# C64 register map
Vendor: Commodore Business Machines; Series: Commodore 64; File version: 0.1.0
CPU: other r0p0, little endian, no MPU, no FPU, 2 interrupt priority bits
Registers are 8-bit, read-write, no defined reset value unless marked. A register's access mark holds for its fields unless they carry their own. Offsets are from the block's base; [hi:lo] are bit positions; lines under a group give offsets from that group; {n}, {i} and the like mark numbered series.

## CPUPORT — MOS 6510 on-chip I/O port at addresses 0x0000-0x0001: memory banking control and Datassette lines. KERNAL reset writes D6510=0x2F, R6510=0x37. baseAddress 0 puts D6510 at address 0, where the generated Periph Deref would form a null reference, so this peripheral is hand-written over the generated output by svd/generate_c64_pac.sh, Fix 5.
Base 0x00000000
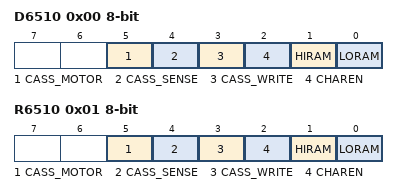
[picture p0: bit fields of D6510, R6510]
0x00 D6510 — Data-direction register for the 6510's on-chip I/O port (R6510): one bit per line, 1 = output, 0 = input. The 6510 is a 6502 with this 6-bit port bolted on; it is the whole reason the C64 can map 64 KiB RAM + 20 KiB ROM + 4 KiB I/O (= 88 KiB (!)) into a single 64 KiB address space with no external MMU. KERNAL reset writes 0x2F (0b0010_1111): lines 0-3 and 5 are outputs, line 4 (cassette sense) is an input, and bits 6-7 are unused (no port line). Written before R6510 during reset. The RAM byte physically at 0x0000 still exists but is hidden behind the port.
  [all] fields
    0=Input; 1=Output
  [5] CASS_MOTOR — Direction of the CASS_MOTOR line (R6510 bit 5)
  [4] CASS_SENSE — Direction of the CASS_SENSE line (R6510 bit 4)
  [3] CASS_WRITE — Direction of the CASS_WRITE line (R6510 bit 3)
  [2] CHAREN — Direction of the CHAREN line (R6510 bit 2)
  [1] HIRAM — Direction of the HIRAM line (R6510 bit 1)
  [0] LORAM — Direction of the LORAM line (R6510 bit 0)
0x01 R6510 — Banking and Datassette port. Reads return pin state for input bits.
  [5] CASS_MOTOR — Datassette motor: 0 = on, 1 = off
    0=Running; 1=Stopped
  [4] CASS_SENSE — Datassette sense (input): 0 = a button is pressed
    0=Pressed; 1=Released
  [3] CASS_WRITE — Datassette write line
  [2] CHAREN — 1 = I/O at 0xD000-0xDFFF, 0 = character ROM (RAM if LORAM=HIRAM=0)
    0=CharRom; 1=Io
  [1] HIRAM — 1 = KERNAL ROM at 0xE000-0xFFFF, 0 = RAM
    0=Ram; 1=KernalRom
  [0] LORAM — 1 = BASIC ROM at 0xA000-0xBFFF (with HIRAM=1), 0 = RAM
    0=Ram; 1=BasicRom

## SID — SID sound interface (6581/8580) at 0xD400. Register image repeats every 0x20 bytes through 0xD7FF. Voice and filter registers are write-only: reads return a decaying copy of the last value written to any SID register, not register contents (not modeled here). POTX/POTY digitize the RC discharge time of the paddle inputs selected by CIA1.CIAPRA bits 6-7.
Base 0x0000D400
{0x0+7i} VOICE{i} (i=0..2) group — Voice {i}
  0x00 FRELO wo — Oscillator frequency bits 7:0
    [7:0] FREQUENCY — Oscillator frequency, low 8 bits
  0x01 FREHI wo — Oscillator frequency bits 15:8
    [7:0] FREQUENCY — Oscillator frequency, high 8 bits
  0x02 PWLO wo — Pulse width bits 7:0
    [7:0] PULSE_WAVEFORM_WIDTH — Pulse waveform width, low 8 bits
  0x03 PWHI wo — Pulse width bits 11:8 (bits 4-7 unused)
    [3:0] PULSE_WAVEFORM_WIDTH — Pulse width bits 11:8
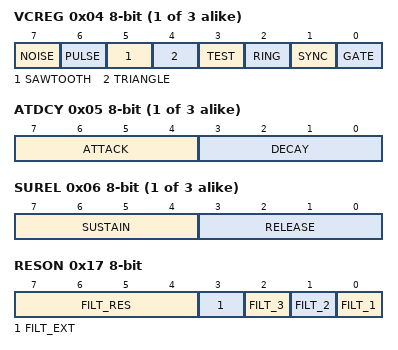
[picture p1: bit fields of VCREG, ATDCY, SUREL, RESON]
  0x04 VCREG wo — Voice control
    [7] NOISE — Noise waveform
      0=Disabled; 1=Enabled
    [6] PULSE — Pulse waveform
      0=Disabled; 1=Enabled
    [5] SAWTOOTH — Sawtooth waveform
      0=Disabled; 1=Enabled
    [4] TRIANGLE — Triangle waveform
      0=Disabled; 1=Enabled
    [3] TEST — Reset and hold the oscillator (Disabled = held)
      0=Enabled; 1=Disabled
    [2] RING — Ring modulation with the preceding voice (triangle output)
      0=Disabled; 1=Enabled
    [1] SYNC — Hard-sync oscillator with the preceding voice
      0=Disabled; 1=Enabled
    [0] GATE — Envelope gate: 0 starts release, 1 starts attack-decay-sustain
      0=StartR; 1=StartADS
  0x05 ATDCY wo — Envelope attack/decay
    [7:4] ATTACK — Attack rate
    [3:0] DECAY — Decay rate
  0x06 SUREL wo — Envelope sustain/release
    [7:4] SUSTAIN — Sustain level
    [3:0] RELEASE — Release rate
0x15 CUTLO wo — Filter cutoff bits 2:0 (bits 3-7 unused)
  [2:0] FILTER_CUTOFF_FREQ — Filter cutoff bits 2:0
0x16 CUTHI wo — Filter cutoff bits 10:3
  [7:0] FILTER_CUTOFF_FREQ — Filter cutoff frequency, high 8 bits
0x17 RESON wo — Filter resonance and routing
  [7:4] FILT_RES — Filter resonance (0-15)
  [3] FILT_EXT — Route external input through the filter
    0=Disabled; 1=Enabled
  [2] FILT_3 — Route voice 3 through the filter
    0=Disabled; 1=Enabled
  [1] FILT_2 — Route voice 2 through the filter
    0=Disabled; 1=Enabled
  [0] FILT_1 — Route voice 1 through the filter
    0=Disabled; 1=Enabled
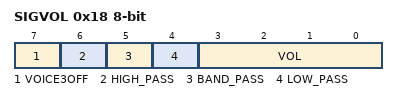
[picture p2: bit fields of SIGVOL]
0x18 SIGVOL wo — Filter mode and master volume
  [7] VOICE3OFF — Voice 3 audio output (Disabled = disconnected)
    0=Enabled; 1=Disabled
  [6] HIGH_PASS — High-pass filter output
    0=Disabled; 1=Enabled
  [5] BAND_PASS — Band-pass filter output
    0=Disabled; 1=Enabled
  [4] LOW_PASS — Low-pass filter output
    0=Disabled; 1=Enabled
  [3:0] VOL — Master volume (0-15)
0x19 POTX ro — Paddle X digitized position (updated every 512 cycles)
0x1A POTY ro — Paddle Y digitized position
0x1B RANDOM ro — Voice 3 oscillator output (usable as entropy with noise waveform)
0x1C ENV3 ro — Voice 3 envelope output

## COLORRAM — 1024 nybbles of static color RAM at 0xD800-0xDBFF, always visible when I/O is banked in, independent of the VIC bank. Only bits 3:0 are stored; bits 7:4 read as whatever the VIC last placed on its data bus (treat reads as 4-bit). The first 1000 (0xD800-0xDBE7) back the 40x25 text/bitmap display; the remaining 24 (0xDBE8-0xDBFF) are unused by the VIC but are real 4-bit cells, usable as scratch.
Base 0x0000D800
{0x0+i} CRAM{i} (i=0..1023) — Color cell (bits 3:0)
  [3:0] COLOR — Color of this cell
    0=Black; 1=White; 2=Red; 3=Cyan; 4=Purple; 5=Green; 6=Blue; 7=Yellow; 8=Orange; 9=Brown; 10=LightRed; 11=DarkGray; 12=MediumGray; 13=LightGreen; 14=LightBlue; 15=LightGray

## IO1 — Expansion (cartridge) port chip-select window: the PLA asserts /IO1 for any access in 0xDE00-0xDEFF. No on-board device responds; contents are defined by the inserted cartridge. With nothing connected, reads return open bus (a decaying copy of the last byte on the data bus) and writes have no effect.
Base 0x0000DE00
Same registers: IO2 0x0000DF00
{0x0+i} BYTE{i} (i=0..255) — Cartridge-defined
